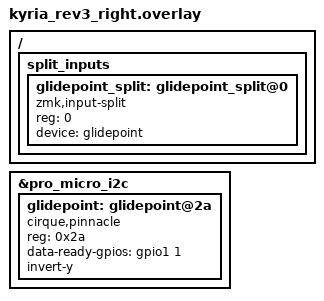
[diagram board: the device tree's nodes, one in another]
/*
 * Cirque Pinnacle (TM040040) trackpad on the RIGHT half (split peripheral).
 *
 * - Communicates over I2C (address 0x2A), the on-board resistor having been
 *   removed to select I2C mode instead of SPI.
 * - The DR (data-ready) line is wired to P1.01 on the nice!nano.
 * - The input is forwarded to the central half through a zmk,input-split
 *   channel (reg = 0), which is matched by the same channel on the left half.
 */

#include <dt-bindings/gpio/gpio.h>

/ {
	split_inputs {
		#address-cells = <1>;
		#size-cells = <0>;

		glidepoint_split: glidepoint_split@0 {
			compatible = "zmk,input-split";
			reg = <0>;
			device = <&glidepoint>;
		};
	};
};

&pro_micro_i2c {
	status = "okay";

	glidepoint: glidepoint@2a {
		compatible = "cirque,pinnacle";
		reg = <0x2a>;
		status = "okay";
		data-ready-gpios = <&gpio1 1 (GPIO_ACTIVE_HIGH)>;
		invert-y;
	};
};
